# MDR1901VC1T register map
Registers are 32-bit, access not given, no defined reset value unless marked. A register's access mark holds for its fields unless they carry their own. Addresses are absolute; registers are grouped by the start of their names; [hi:lo] are bit positions; {n}, {i} and the like mark numbered series.

## DMA
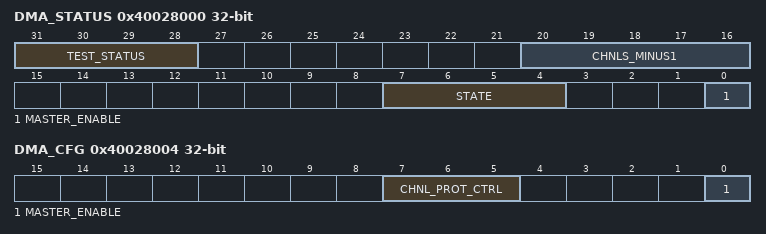
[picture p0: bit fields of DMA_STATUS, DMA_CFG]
0x40028000 DMA_STATUS
  [31:28] TEST_STATUS, [20:16] CHNLS_MINUS1, [7:4] STATE, [0] MASTER_ENABLE
0x40028004 DMA_CFG
  [7:5] CHNL_PROT_CTRL, [0] MASTER_ENABLE
0x40028008 DMA_CTRL_BASE_PTR
0x4002800C DMA_ALT_CTRL_BASE_PTR
0x40028010 DMA_WAITONREQ_STATUS
0x40028014 DMA_CHNL_SW_REQUEST
0x40028018 DMA_CHNL_USEBURST_SET
0x4002801C DMA_CHNL_USEBURST_CLR
0x40028020 DMA_CHNL_REQ_MASK_SET
0x40028024 DMA_CHNL_REQ_MASK_CLR
0x40028028 DMA_CHNL_ENABLE_SET
0x4002802C DMA_CHNL_ENABLE_CLR
0x40028030 DMA_CHNL_PRI_ALT_SET
0x40028034 DMA_CHNL_PRI_ALT_CLR
0x40028038 DMA_CHNL_PRIORITY_SET
0x4002803C DMA_CHNL_PRIORITY_CLR
0x4002804C DMA_ERR_CLR
  [0] ERR_CLR

## SDIO
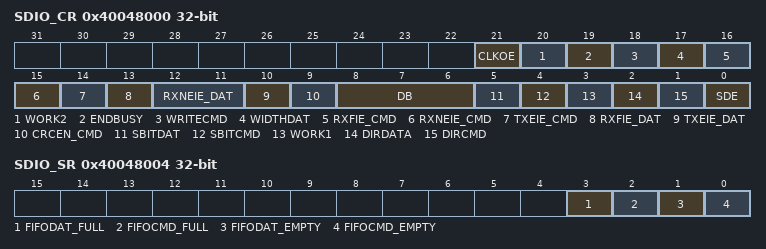
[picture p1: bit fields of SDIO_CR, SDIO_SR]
0x40048000 SDIO_CR
  [21] CLKOE, [20] WORK2, [19] ENDBUSY, [18] WRITECMD, [17] WIDTHDAT, [16] RXFIE_CMD, [15] RXNEIE_CMD, [14] TXEIE_CMD, [13] RXFIE_DAT, [12:11] RXNEIE_DAT, [10] TXEIE_DAT, [9] CRCEN_CMD, [8:6] DB, [5] SBITDAT, [4] SBITCMD, [3] WORK1, [2] DIRDATA, [1] DIRCMD, [0] SDE
0x40048004 SDIO_SR
  [3] FIFODAT_FULL, [2] FIFOCMD_FULL, [1] FIFODAT_EMPTY, [0] FIFOCMD_EMPTY
0x40048008 SDIO_CMDDR
0x4004800C SDIO_DATDR
0x40048010 SDIO_CMDCRC
  [6:0] CMDCRC
{0x40048014+4i} SDIO_DAT{i}CRC (i=0..3)
  [15:0] DAT{i}CRC
0x40048024 SDIO_CMD_TRANSFER
  [15:0] CMD_TRANSFER
0x40048028 SDIO_DAT_TRANSFER
  [15:0] DAT_TRANSFER

## I2C
0x40050000 I2C_PRL
  [7:0] PR
0x40050004 I2C_PRH
  [7:0] PR
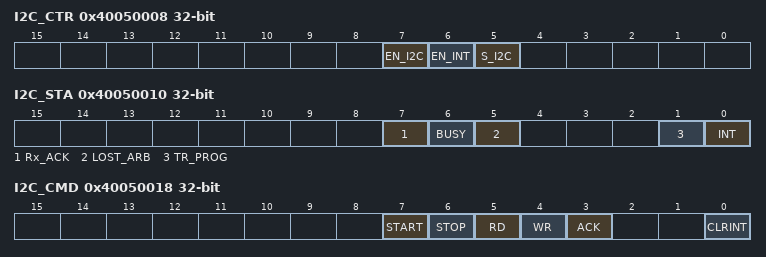
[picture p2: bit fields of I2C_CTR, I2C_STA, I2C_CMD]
0x40050008 I2C_CTR
  [7] EN_I2C, [6] EN_INT, [5] S_I2C
0x4005000C I2C_RXD
  [7:0] RXD
0x40050010 I2C_STA
  [7] Rx_ACK, [6] BUSY, [5] LOST_ARB, [1] TR_PROG, [0] INT
0x40050014 I2C_TXD
  [7:0] TXD
0x40050018 I2C_CMD
  [7] START, [6] STOP, [5] RD, [4] WR, [3] ACK, [0] CLRINT

## WWDG
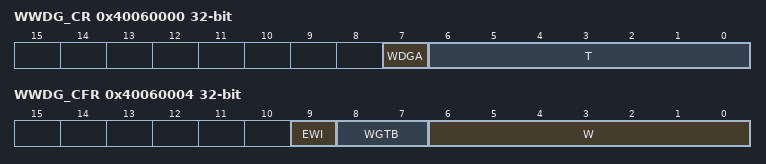
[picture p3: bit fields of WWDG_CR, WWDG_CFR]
0x40060000 WWDG_CR
  [7] WDGA, [6:0] T
0x40060004 WWDG_CFR
  [9] EWI, [8:7] WGTB, [6:0] W
0x40060008 WWDG_SR
  [0] EWIF

## IWDG
0x40068000 IWDG_KR
  [15:0] KEY
0x40068004 IWDG_PR
  [2:0] PR
0x40068008 IWDG_RLR
  [11:0] RLR
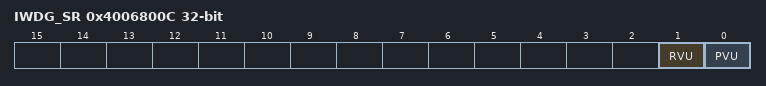
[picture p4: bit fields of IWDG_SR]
0x4006800C IWDG_SR
  [1] RVU, [0] PVU

## ADC1
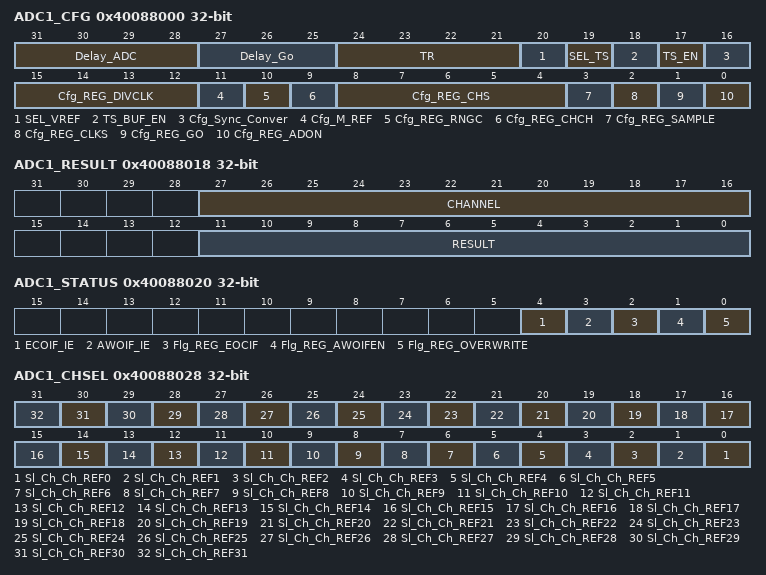
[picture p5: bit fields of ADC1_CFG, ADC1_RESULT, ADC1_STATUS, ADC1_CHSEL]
0x40088000 ADC1_CFG
  [31:28] Delay_ADC, [27:25] Delay_Go, [24:21] TR, [20] SEL_VREF, [19] SEL_TS, [18] TS_BUF_EN, [17] TS_EN, [16] Cfg_Sync_Conver, [15:12] Cfg_REG_DIVCLK, [11] Cfg_M_REF, [10] Cfg_REG_RNGC, [9] Cfg_REG_CHCH, [8:4] Cfg_REG_CHS, [3] Cfg_REG_SAMPLE, [2] Cfg_REG_CLKS, [1] Cfg_REG_GO, [0] Cfg_REG_ADON
0x40088008 ADC1_H_LEVEL
  [11:0] REG_H_LEVEL
0x40088010 ADC1_L_LEVEL
  [11:0] REG_L_LEVEL
0x40088018 ADC1_RESULT
  [27:16] CHANNEL, [11:0] RESULT
0x40088020 ADC1_STATUS
  [4] ECOIF_IE, [3] AWOIF_IE, [2] Flg_REG_EOCIF, [1] Flg_REG_AWOIFEN, [0] Flg_REG_OVERWRITE
0x40088028 ADC1_CHSEL
  [n] Sl_Ch_Ch_REF{n} (n=0..31)

## ADC2
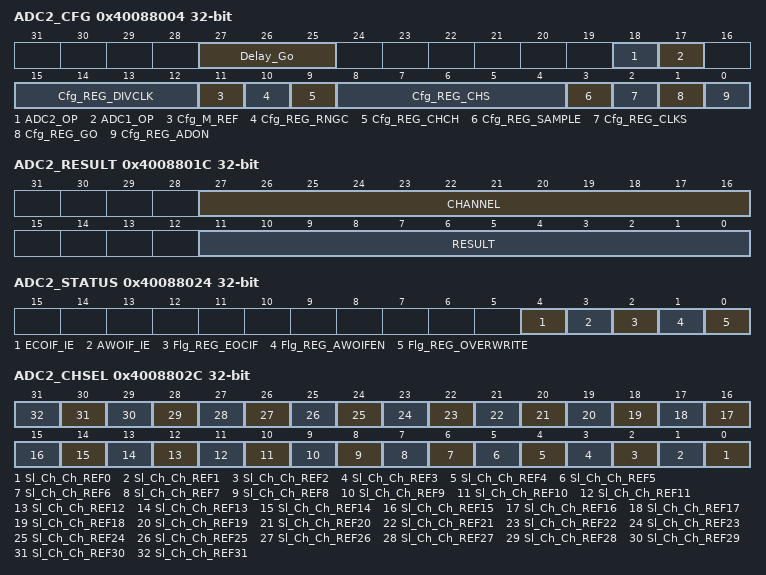
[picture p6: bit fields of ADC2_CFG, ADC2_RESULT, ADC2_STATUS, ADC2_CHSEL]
0x40088004 ADC2_CFG
  [27:25] Delay_Go, [18] ADC2_OP, [17] ADC1_OP, [15:12] Cfg_REG_DIVCLK, [11] Cfg_M_REF, [10] Cfg_REG_RNGC, [9] Cfg_REG_CHCH, [8:4] Cfg_REG_CHS, [3] Cfg_REG_SAMPLE, [2] Cfg_REG_CLKS, [1] Cfg_REG_GO, [0] Cfg_REG_ADON
0x4008800C ADC2_H_LEVEL
  [11:0] REG_H_LEVEL
0x40088014 ADC2_L_LEVEL
  [11:0] REG_L_LEVEL
0x4008801C ADC2_RESULT
  [27:16] CHANNEL, [11:0] RESULT
0x40088024 ADC2_STATUS
  [4] ECOIF_IE, [3] AWOIF_IE, [2] Flg_REG_EOCIF, [1] Flg_REG_AWOIFEN, [0] Flg_REG_OVERWRITE
0x4008802C ADC2_CHSEL
  [n] Sl_Ch_Ch_REF{n} (n=0..31)

## DAC
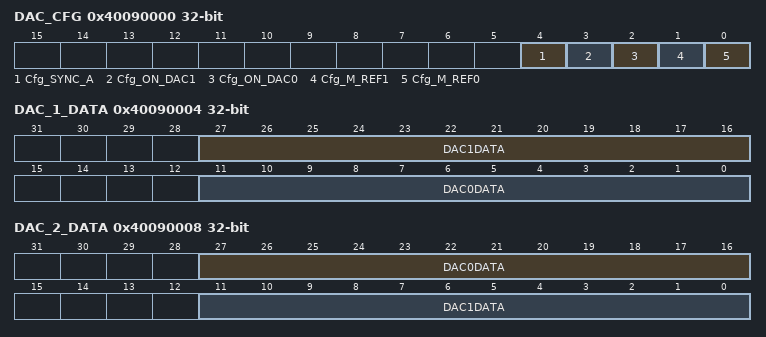
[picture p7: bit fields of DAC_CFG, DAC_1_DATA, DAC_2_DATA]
0x40090000 DAC_CFG
  [4] Cfg_SYNC_A, [3] Cfg_ON_DAC1, [2] Cfg_ON_DAC0, [1] Cfg_M_REF1, [0] Cfg_M_REF0
0x40090004 DAC_1_DATA
  [27:16] DAC1DATA, [11:0] DAC0DATA
0x40090008 DAC_2_DATA
  [27:16] DAC0DATA, [11:0] DAC1DATA

## COMP
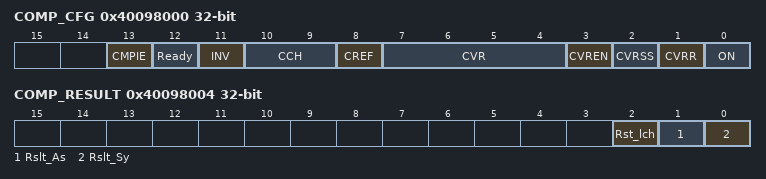
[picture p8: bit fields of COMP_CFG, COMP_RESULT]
0x40098000 COMP_CFG
  [13] CMPIE, [12] Ready, [11] INV, [10:9] CCH, [8] CREF, [7:4] CVR, [3] CVREN, [2] CVRSS, [1] CVRR, [0] ON
0x40098004 COMP_RESULT
  [2] Rst_lch, [1] Rslt_As, [0] Rslt_Sy
0x40098008 COMP_RESULT_LATCH
  [0] Rst_lch
